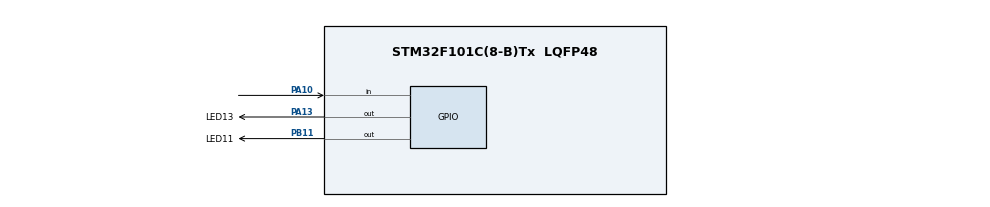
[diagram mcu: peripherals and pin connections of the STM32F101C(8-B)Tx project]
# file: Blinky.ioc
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Mcu.Family=STM32F1
Mcu.Name=STM32F101C(8-B)Tx
Mcu.Package=LQFP48
NVIC.PriorityGroup=NVIC_PRIORITYGROUP_4
PA10.Signal=GPIO_Input
PA13.GPIO_Label=LED13
PA13.GPIO_Speed=GPIO_SPEED_FREQ_HIGH
PA13.Signal=GPIO_Output
PB11.GPIO_Label=LED11
PB11.GPIO_Speed=GPIO_SPEED_FREQ_HIGH
PB11.Signal=GPIO_Output
ProjectManager.HeapSize=0x200
ProjectManager.StackSize=0x400
ProjectManager.TargetToolchain=STM32CubeIDE
RCC.APB1Freq_Value=8000000
RCC.APB2Freq_Value=8000000
board=custom

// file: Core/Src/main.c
/* USER CODE BEGIN Header */
/**
 ******************************************************************************
 * @file           : main.c
 * @brief          : Main program body
 ******************************************************************************
 * @attention
 *
 * Copyright (c) 2023 STMicroelectronics.
 * All rights reserved.
 *
 * This software is licensed under terms that can be found in the LICENSE file
 * in the root directory of this software component.
 * If no LICENSE file comes with this software, it is provided AS-IS.
 *
 ******************************************************************************
 */
/* USER CODE END Header */
#include "main.h"

void SystemClock_Config(void);
static void MX_GPIO_Init(void);

int main(void)
{

  /* MCU Configuration--------------------------------------------------------*/

  /* Reset of all peripherals, Initializes the Flash interface and the Systick. */
  HAL_Init();

  /* Configure the system clock */
  SystemClock_Config();

  /* Initialize all configured peripherals */
  MX_GPIO_Init();
  /* USER CODE BEGIN 2 */
  int test=100;
  //HAL_Delay(2000);
  //HAL_GPIO_TogglePin(GPIOC, GPIO_PIN_13);
  /* USER CODE END 2 */

  /* Infinite loop */
    while (1)
    {

    /* USER CODE BEGIN 3 */
    	//if(test>10){
			// Toggle the LED

    	    HAL_GPIO_WritePin(GPIOC, LED13_Pin, 1);
			// Wait for 500 ms
			HAL_Delay(1000);
			HAL_GPIO_WritePin(GPIOC, LED13_Pin, 0);

			HAL_Delay(1000);
    	//}

    }
  /* USER CODE END 3 */
}

void SystemClock_Config(void)
{
  RCC_OscInitTypeDef RCC_OscInitStruct = {0};
  RCC_ClkInitTypeDef RCC_ClkInitStruct = {0};

  /** Initializes the RCC Oscillators according to the specified parameters
  * in the RCC_OscInitTypeDef structure.
  */
  RCC_OscInitStruct.OscillatorType = RCC_OSCILLATORTYPE_HSI;
  RCC_OscInitStruct.HSIState = RCC_HSI_ON;
  RCC_OscInitStruct.HSICalibrationValue = RCC_HSICALIBRATION_DEFAULT;
  RCC_OscInitStruct.PLL.PLLState = RCC_PLL_NONE;
  if (HAL_RCC_OscConfig(&RCC_OscInitStruct) != HAL_OK)
  {
    Error_Handler();
  }

  /** Initializes the CPU, AHB and APB buses clocks
  */
  RCC_ClkInitStruct.ClockType = RCC_CLOCKTYPE_HCLK|RCC_CLOCKTYPE_SYSCLK
                              |RCC_CLOCKTYPE_PCLK1|RCC_CLOCKTYPE_PCLK2;
  RCC_ClkInitStruct.SYSCLKSource = RCC_SYSCLKSOURCE_HSI;
  RCC_ClkInitStruct.AHBCLKDivider = RCC_SYSCLK_DIV1;
  RCC_ClkInitStruct.APB1CLKDivider = RCC_HCLK_DIV1;
  RCC_ClkInitStruct.APB2CLKDivider = RCC_HCLK_DIV1;

  if (HAL_RCC_ClockConfig(&RCC_ClkInitStruct, FLASH_LATENCY_0) != HAL_OK)
  {
    Error_Handler();
  }
}

static void MX_GPIO_Init(void)
{
  GPIO_InitTypeDef GPIO_InitStruct = {0};

  /* GPIO Ports Clock Enable */
  __HAL_RCC_GPIOB_CLK_ENABLE();
  __HAL_RCC_GPIOA_CLK_ENABLE();

  /*Configure GPIO pin Output Level */
  HAL_GPIO_WritePin(LED11_GPIO_Port, LED11_Pin, GPIO_PIN_RESET);

  /*Configure GPIO pin Output Level */
  HAL_GPIO_WritePin(LED13_GPIO_Port, LED13_Pin, GPIO_PIN_RESET);

  /*Configure GPIO pin : LED11_Pin */
  GPIO_InitStruct.Pin = LED11_Pin;
  GPIO_InitStruct.Mode = GPIO_MODE_OUTPUT_PP;
  GPIO_InitStruct.Pull = GPIO_NOPULL;
  GPIO_InitStruct.Speed = GPIO_SPEED_FREQ_HIGH;
  HAL_GPIO_Init(LED11_GPIO_Port, &GPIO_InitStruct);

  /*Configure GPIO pin : PA10 */
  GPIO_InitStruct.Pin = GPIO_PIN_10;
  GPIO_InitStruct.Mode = GPIO_MODE_INPUT;
  GPIO_InitStruct.Pull = GPIO_NOPULL;
  HAL_GPIO_Init(GPIOA, &GPIO_InitStruct);

  /*Configure GPIO pin : LED13_Pin */
  GPIO_InitStruct.Pin = LED13_Pin;
  GPIO_InitStruct.Mode = GPIO_MODE_OUTPUT_PP;
  GPIO_InitStruct.Pull = GPIO_NOPULL;
  GPIO_InitStruct.Speed = GPIO_SPEED_FREQ_HIGH;
  HAL_GPIO_Init(LED13_GPIO_Port, &GPIO_InitStruct);

}

void Error_Handler(void)
{
    __disable_irq();
    while (1)
    {
    }
}
